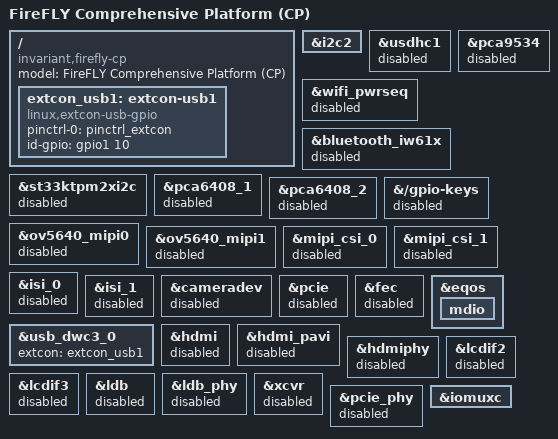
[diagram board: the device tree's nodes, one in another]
// SPDX-License-Identifier: (GPL-2.0+ OR MIT)
/*
 * FireFLY Comprehensive Platform (CP) carrier for DART-MX8M-PLUS
 *
 * The CP carrier is derived from the Variscite Sonata (formerly
 * DT8MCustomBoard) carrier. Start from the Sonata description and drop or
 * disable what the CP does not have, so that Variscite updates to the
 * Sonata DTS keep applying.
 *
 * Copyright 2019 NXP
 * Copyright 2020-2026 Variscite Ltd.
 * Copyright 2023-2026 Invariant Corporation
 */

#include "imx8mp-var-dart-sonata.dts"

/ {
	model = "FireFLY Comprehensive Platform (CP)";
	compatible = "invariant,firefly-cp",
		     "variscite,var-dart-mx8mp",
		     "fsl,imx8mp";

	/delete-node/ sound-hdmi;
	/delete-node/ sound-xcvr;

	/* USB OTG role from the ID pin (replaces the Sonata PTN5150) */
	extcon_usb1: extcon-usb1 {
		compatible = "linux,extcon-usb-gpio";
		pinctrl-names = "default";
		pinctrl-0 = <&pinctrl_extcon>;
		id-gpio = <&gpio1 10 GPIO_ACTIVE_HIGH>;
	};
};

&i2c2 {
	/delete-node/ touchscreen@38;
	/delete-node/ typec@3d;
};

/* FireFLY does not use the SOM WiFi/BT module (IW612 on 2.x, BCM43xx on 1.x) */
&usdhc1 {
	status = "disabled";
};

&wifi_pwrseq {
	status = "disabled";
};

&bluetooth_iw61x {
	status = "disabled";
};

/* Sonata-only I2C devices */
&pca9534 {
	status = "disabled";
};

&st33ktpm2xi2c {
	status = "disabled";
};

/*
 * The CP has no Sonata PCA6408 I/O expanders, so nothing wired through them
 * (keys, cameras, PCIe reset, second Ethernet PHY reset) can work.
 */
&pca6408_1 {
	status = "disabled";
};

&pca6408_2 {
	status = "disabled";
};

&{/gpio-keys} {
	status = "disabled";
};

&ov5640_mipi0 {
	status = "disabled";
};

&ov5640_mipi1 {
	status = "disabled";
};

&mipi_csi_0 {
	status = "disabled";
};

&mipi_csi_1 {
	status = "disabled";
};

&isi_0 {
	status = "disabled";
};

&isi_1 {
	status = "disabled";
};

&cameradev {
	status = "disabled";
};

&pcie {
	status = "disabled";
};

/*
 * Single Ethernet port: EQOS with the SOM's ADIN1300. The FEC and its PHY on
 * the EQOS MDIO bus are Sonata-only; with FEC enabled it registers first and
 * takes eth0, while FireFLY expects the EQOS port as eth0.
 */
&fec {
	status = "disabled";
	/delete-property/ phy-handle;
};

&eqos {
	mdio {
		/delete-node/ ethernet-phy@1;
	};
};

&usb_dwc3_0 {
	extcon = <&extcon_usb1>;
	/delete-property/ usb-role-switch;
	/delete-node/ port;
};

/* No display or HDMI audio; the HDMI pads are reused for I2C5/I2C6 */
&hdmi {
	status = "disabled";
};

&hdmi_pavi {
	status = "disabled";
};

&hdmiphy {
	status = "disabled";
};

&lcdif2 {
	status = "disabled";
};

&lcdif3 {
	status = "disabled";
};

&ldb {
	status = "disabled";
};

&ldb_phy {
	status = "disabled";
};

&xcvr {
	status = "disabled";
};

&pcie_phy {
	status = "disabled";
};

&iomuxc {
	/* Drop the HDMI pad hog; those pads are muxed as I2C5/I2C6 */
	/delete-property/ pinctrl-names;
	/delete-property/ pinctrl-0;
};
